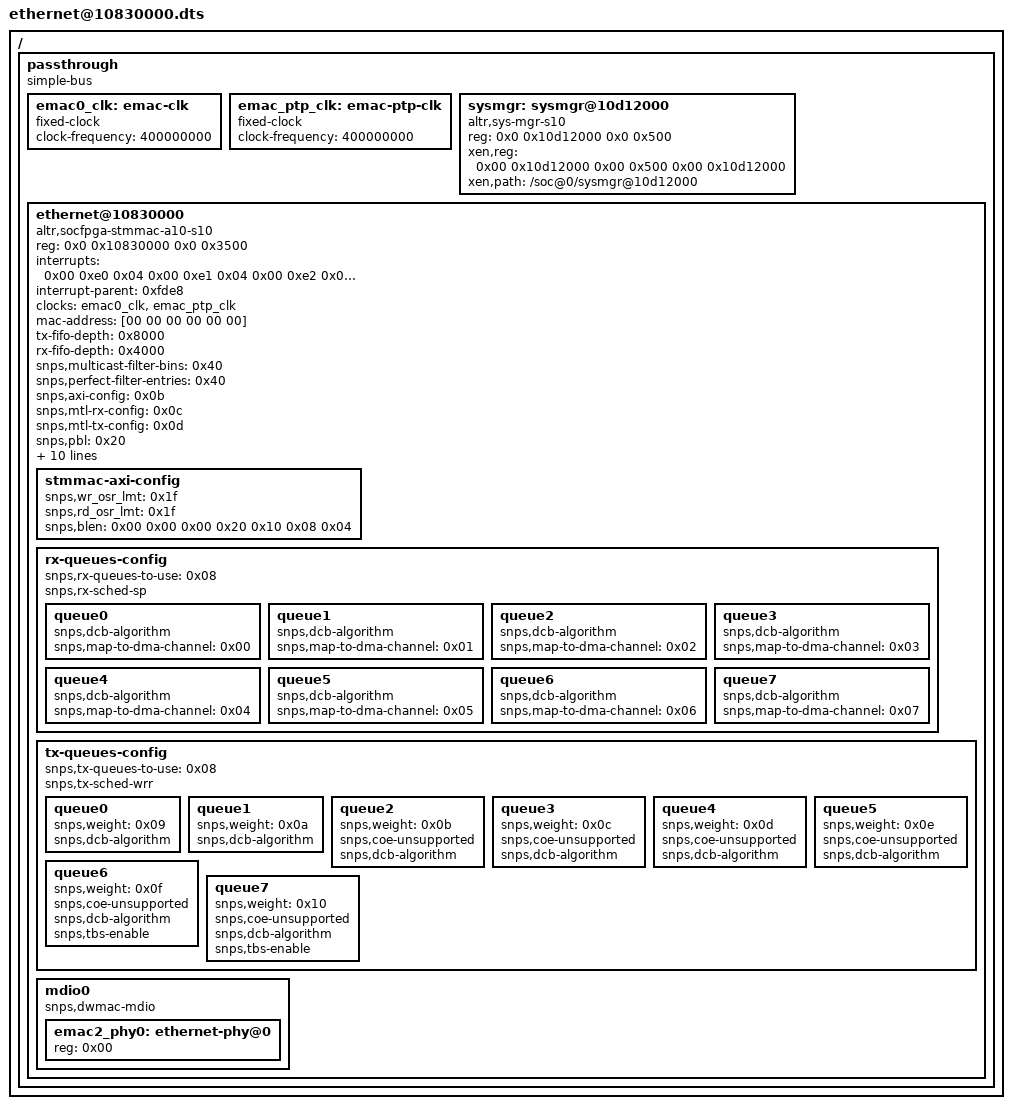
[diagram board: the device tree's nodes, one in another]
/* SPDX-License-Identifier: MIT-0 */
/dts-v1/;

/ {
	#address-cells = <0x02>;
	#size-cells = <0x02>;

	passthrough {
		compatible = "simple-bus";
		ranges;
		#address-cells = <0x02>;
		#size-cells = <0x02>;

		emac0_clk: emac-clk {
			#clock-cells = <0x00>;
			compatible = "fixed-clock";
			clock-frequency = <400000000>;
		};

		emac_ptp_clk: emac-ptp-clk {
			#clock-cells = <0x00>;
			compatible = "fixed-clock";
			clock-frequency = <400000000>;
		};

                sysmgr: sysmgr@10d12000 {
                        compatible = "altr,sys-mgr-s10","altr,sys-mgr";
                        reg = <0x0 0x10d12000 0x0 0x500>;
                        status = "okay";
                        xen,reg = <0x00 0x10d12000 0x00 0x500 0x00 0x10d12000>;
                        xen,path = "/soc@0/sysmgr@10d12000";
                };

		ethernet@10830000 {
			compatible = "altr,socfpga-stmmac-a10-s10\0snps,dwxgmac-2.10\0snps,dwxgmac";
			reg = <0x0 0x10830000 0x0 0x3500>;
			interrupts = <0x00 0xe0 0x04 0x00 0xe1 0x04 0x00 0xe2 0x04 0x00 0xe3 0x04 0x00 0xe4 0x04 0x00 0xe5 0x04 0x00 0xe6 0x04 0x00 0xe7 0x04 0x00 0xe8 0x04 0x00 0xe9 0x04 0x00 0xea 0x04 0x00 0xeb 0x04 0x00 0xec 0x04 0x00 0xed 0x04 0x00 0xee 0x04 0x00 0xef 0x04 0x00 0xf0 0x04>;
			interrupt-names = "macirq\0macirq_tx0\0macirq_tx1\0macirq_tx2\0macirq_tx3\0macirq_tx4\0macirq_tx5\0macirq_tx6\0macirq_tx7\0macirq_rx0\0macirq_rx1\0macirq_rx2\0macirq_rx3\0macirq_rx4\0macirq_rx5\0macirq_rx6\0macirq_rx7";
			interrupt-parent = <0xfde8>;
			clocks = <&emac0_clk &emac_ptp_clk>;
			clock-names = "stmmaceth\0ptp_ref";
			mac-address = [00 00 00 00 00 00];
			tx-fifo-depth = <0x8000>;
			rx-fifo-depth = <0x4000>;
			snps,multicast-filter-bins = <0x40>;
			snps,perfect-filter-entries = <0x40>;
			snps,axi-config = <0x0b>;
			snps,mtl-rx-config = <0x0c>;
			snps,mtl-tx-config = <0x0d>;
			snps,pbl = <0x20>;
			snps,pblx8;
			snps,multi-irq-en;
			snps,tso;
			snps,rx-vlan-offload;
			altr,sysmgr-syscon = <&sysmgr 0x4c 0x00>;
			altr,smtg-hub;
			snps,clk-csr = <0x00>;
			status = "okay";
			phy-mode = "rgmii";
			phy-handle = <&emac2_phy0>;
			max-frame-size = <0x2328>;

			stmmac-axi-config {
				snps,wr_osr_lmt = <0x1f>;
				snps,rd_osr_lmt = <0x1f>;
				snps,blen = <0x00 0x00 0x00 0x20 0x10 0x08 0x04>;
				phandle = <0x0b>;
			};

			rx-queues-config {
				snps,rx-queues-to-use = <0x08>;
				snps,rx-sched-sp;
				phandle = <0x0c>;

				queue0 {
					snps,dcb-algorithm;
					snps,map-to-dma-channel = <0x00>;
				};

				queue1 {
					snps,dcb-algorithm;
					snps,map-to-dma-channel = <0x01>;
				};

				queue2 {
					snps,dcb-algorithm;
					snps,map-to-dma-channel = <0x02>;
				};

				queue3 {
					snps,dcb-algorithm;
					snps,map-to-dma-channel = <0x03>;
				};

				queue4 {
					snps,dcb-algorithm;
					snps,map-to-dma-channel = <0x04>;
				};

				queue5 {
					snps,dcb-algorithm;
					snps,map-to-dma-channel = <0x05>;
				};

				queue6 {
					snps,dcb-algorithm;
					snps,map-to-dma-channel = <0x06>;
				};

				queue7 {
					snps,dcb-algorithm;
					snps,map-to-dma-channel = <0x07>;
				};
			};

			tx-queues-config {
				snps,tx-queues-to-use = <0x08>;
				snps,tx-sched-wrr;
				phandle = <0x0d>;

				queue0 {
					snps,weight = <0x09>;
					snps,dcb-algorithm;
				};

				queue1 {
					snps,weight = <0x0a>;
					snps,dcb-algorithm;
				};

				queue2 {
					snps,weight = <0x0b>;
					snps,coe-unsupported;
					snps,dcb-algorithm;
				};

				queue3 {
					snps,weight = <0x0c>;
					snps,coe-unsupported;
					snps,dcb-algorithm;
				};

				queue4 {
					snps,weight = <0x0d>;
					snps,coe-unsupported;
					snps,dcb-algorithm;
				};

				queue5 {
					snps,weight = <0x0e>;
					snps,coe-unsupported;
					snps,dcb-algorithm;
				};

				queue6 {
					snps,weight = <0x0f>;
					snps,coe-unsupported;
					snps,dcb-algorithm;
					snps,tbs-enable;
				};

				queue7 {
					snps,weight = <0x10>;
					snps,coe-unsupported;
					snps,dcb-algorithm;
					snps,tbs-enable;
				};
			};

			mdio0 {
				#address-cells = <0x01>;
				#size-cells = <0x00>;
				compatible = "snps,dwmac-mdio";

				emac2_phy0: ethernet-phy@0 {
					reg = <0x00>;
				};
			};
		};
	};
};
